# SIM3U164_B register map
File version: 1
CPU: 
Registers are 32-bit, read-write, reset 0x0 unless marked. A register's access mark holds for its fields unless they carry their own. Offsets are from the block's base; [hi:lo] are bit positions.

## IDAC_1
Base 0x40032000
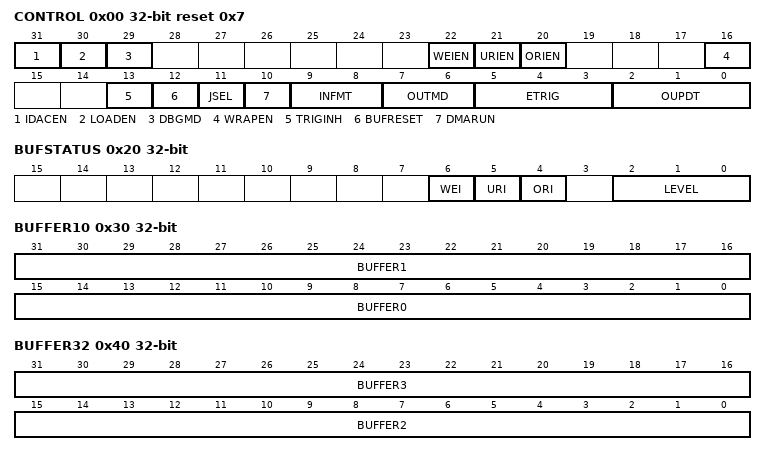
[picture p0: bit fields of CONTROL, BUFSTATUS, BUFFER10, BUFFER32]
0x00 CONTROL reset 0x7 — Module Control
  [31] IDACEN — IDAC Enable.
    0=DISABLED (Disable the IDAC.); 1=ENABLED (Enable the IDAC.)
  [30] LOADEN — Load Resistor Enable.
    0=DISABLED (Disable the internal load resistor.); 1=ENABLED (Enable the internal load resistor.)
  [29] DBGMD — IDAC Debug Mode.
    0=RUN (The IDAC module will continue to operate while the core is halted in debug mode.); 1=HALT (A debug breakpoint will cause the IDAC module to halt.)
  [22] WEIEN — FIFO Went Empty Interrupt Enable.
    0=DISABLED (Disable the FIFO went empty interrupt (WEI).); 1=ENABLED (Enable the FIFO went empty interrupt (WEI).)
  [21] URIEN — FIFO Underrun Interrupt Enable.
    0=DISABLED (Disable the FIFO underrun interrupt (URI).); 1=ENABLED (Enable the FIFO underrun interrupt (URI).)
  [20] ORIEN — FIFO Overrun Interrupt Enable.
    0=DISABLED (Disable the FIFO overrun interrupt (ORI).); 1=ENABLED (Enable the FIFO overrun interrupt (ORI).)
  [16] WRAPEN — Wrap Mode Enable.
    0=DISABLED (The IDAC will not wrap when it reaches the end of the data buffer.); 1=ENABLED (The IDAC will cycle through the data buffer contents.)
  [13] TRIGINH — Trigger Source Inhibit.
    0=INACTIVE (The selected trigger source will cause the IDAC output to update.); 1=ACTIVE (The selected trigger source will not update the IDAC output, except for On-Demand DATA writes.)
  [12] BUFRESET wo — Data Buffer Reset.
    1=RESET (Initiate a data buffer reset.)
  [11] JSEL — Data Justification Select.
    0=RIGHT (Data is right-justified.); 1=LEFT (Data is left-justified.)
  [10] DMARUN
    0=DISABLED (Read: No DMA operations are occurring or the DMA is done. Write: No effect.); 1=ENABLED (Read: A DMA operation is currently in progress. Write: Start a DMA operation.)
  [9:8] INFMT — Data Input Format.
    0=1_10_BIT (Writes are interpreted as one 10-bit sample.); 1=2_10_BIT (Writes are interpreted as two 10-bit samples.); 2=4_8_BIT (Writes are interpreted as four 8-bit samples.)
  [7:6] OUTMD — Output Mode.
    0=0P5_MA (The full-scale output current is 0.5 mA.); 1=1_MA (The full-scale output current is 1 mA.); 2=2_MA (The full-scale output current is 2 mA.)
  [5:3] ETRIG — Edge Trigger Source Select.
    0=DACNT0 (Select DACnT0 (PB3.0) as the IDAC external trigger source.); 1=DACNT1 (Select DACnT1 (PB3.1) as the IDAC external trigger source.); 2=DACNT2 (Select DACnT2 (PB3.2) as the IDAC external trigger source.); 3=DACNT3 (Select DACnT3 (PB3.3) as the IDAC external trigger source.); 4=DACNT4 (Select DACnT4 (RESERVED) as the IDAC external trigger source.); 5=DACNT5 (Select DACnT5 (RESERVED) as the IDAC external trigger source.); 6=DACNT6 (Select DACnT6 (RESERVED) as the IDAC external trigger source.); 7=DACNT7 (Select DACnT7 (SSG0 EX3) as the IDAC external trigger source.)
  [2:0] OUPDT — Output Update Trigger.
    0=DACNT8 (The IDAC output updates using the DACnT8 (Timer 0 Low Overflow) trigger source.); 1=DACNT9 (The IDAC output updates using the DACnT9 (Timer 1 High Overflow) trigger source.); 2=DACNT10 (The IDAC output updates using the DACnT10 (Timer 1 Low Overflow) trigger source.); 3=DACNT11 (The IDAC output updates using the DACnT11 (Timer 1 High Overflow) trigger source.); 4=DACNT12 (The IDAC output updates on the rising edge of the trigger source selected by ETRIG.); 5=DACNT13 (The IDAC output updates on the falling edge of the trigger source selected by ETRIG.); 6=DACNT14 (The IDAC output updates on any edge of the trigger source selected by ETRIG.); 7=DACNT15 (The IDAC output updates on write to DATA register (On Demand).)
0x10 DATA — Output Data
  [31:0] DATA — Output Data.
0x20 BUFSTATUS — FIFO Buffer Status
  [6] WEI — FIFO Went Empty Interrupt Flag.
    0=NOT_SET (Read: A FIFO went empty condition has not occurred. Write: Clear the interrupt.); 1=SET (Read: The FIFO is empty. Write: Force a FIFO went empty interrupt.)
  [5] URI — FIFO Underrun Interrupt Flag.
    0=NOT_SET (Read: A FIFO underrun has not occurred. Write: Clear the interrupt.); 1=SET (Read: A FIFO underrun occurred. Write: Force a FIFO underrun interrupt.)
  [4] ORI — FIFO Overrun Interrupt Flag.
    0=NOT_SET (Read: A FIFO overrun has not occurred. Write: Clear the interrupt.); 1=SET (Read: A FIFO overrun occurred. Write: Force a FIFO overrun interrupt.)
  [2:0] LEVEL ro — FIFO Level.
    0=EMPTY (The data FIFO is empty.); 1=1WORD (The data FIFO contains one word.); 2=2WORDS (The data FIFO contains two words.); 3=3WORDS (The data FIFO contains three words.); 4=4WORDS (The data FIFO is full and contains four words.)
0x30 BUFFER10 — FIFO Buffer Entries 0 and 1
  [31:16] BUFFER1 ro — FIFO Buffer Entry 1.
  [15:0] BUFFER0 ro — FIFO Buffer Entry 0.
0x40 BUFFER32 — FIFO Buffer Entries 2 and 3
  [31:16] BUFFER3 ro — FIFO Buffer Entry 3.
  [15:0] BUFFER2 ro — FIFO Buffer Entry 2.
0x50 GAINADJ reset 0xD — Output Current Gain Adjust
  [4:0] GAINADJ — Output Current Gain Adjust.
